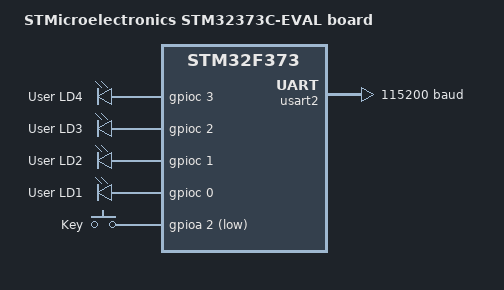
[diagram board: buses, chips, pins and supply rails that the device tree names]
/*
 * Copyright (c) 2017 Linaro Limited
 *
 * SPDX-License-Identifier: Apache-2.0
 */

/dts-v1/;
#include <st/stm32f373.dtsi>

/ {
	model = "STMicroelectronics STM32373C-EVAL board";
	compatible = "st,stm32373c-eval", "st,stm32f373";

	chosen {
		zephyr,console = &usart2;
		zephyr,sram = &sram0;
		zephyr,flash = &flash0;
	};

	leds {
		compatible = "gpio-leds";
		blue_led: led@3 {
			gpios = <&gpioc 3 GPIO_INT_ACTIVE_HIGH>;
			label = "User LD4";
		};
		red_led: led@2 {
			gpios = <&gpioc 2 GPIO_INT_ACTIVE_HIGH>;
			label = "User LD3";
		};
		orange_led: led@1 {
			gpios = <&gpioc 1 GPIO_INT_ACTIVE_HIGH>;
			label = "User LD2";
		};
		green_led: led@0 {
			gpios = <&gpioc 0 GPIO_INT_ACTIVE_HIGH>;
			label = "User LD1";
		};
	};

	gpio_keys {
		compatible = "gpio-keys";
		user_button: button@0 {
			label = "Key";
			gpios = <&gpioa 2 GPIO_INT_ACTIVE_LOW>;
		};
	};

	aliases {
		led3 = &blue_led;
		led2 = &red_led;
		led1 = &orange_led;
		led0 = &green_led;
		sw0 = &user_button;
	};
};

&usart2 {
	current-speed = <115200>;
	pinctrl-0 = <&usart2_pins_d>;
	pinctrl-names = "default";
	status = "ok";
};
